# MSS_GPCFG_REG register map
Vendor: Texas Instruments
Peripheral module from a debugger description file (folder radar).
Registers are 32-bit, read-write, no defined reset value unless marked. A register's access mark holds for its fields unless they carry their own. Offsets are as the file gives them; lines under a group give offsets from that group; [hi:lo] are bit positions; {n}, {i} and the like mark numbered series; 'fields as' and 'values as' point back to an identical list; <NAME> marks a mode.

## MSS_GPCFG_REG
{0x0+4i} GPCFG{i} (i=0..4)
  [31:0] GPCFG{i} — General Purpose config register for SW use.
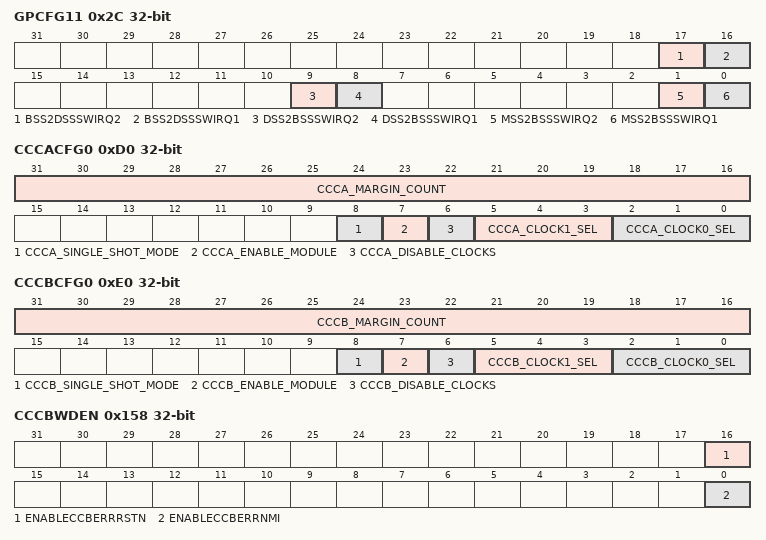
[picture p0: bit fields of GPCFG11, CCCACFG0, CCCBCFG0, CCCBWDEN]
0x2C GPCFG11 access not given
  [17] BSS2DSSSWIRQ2 — Self clearing register bit to generate interrupt to DSP from BSS. Writing a ‘1’ generates a pulse interrupt on one of the interrupt lines to DSP
  [16] BSS2DSSSWIRQ1 — Self clearing register bit to generate interrupt to DSP from BSS. Writing a ‘1’ generates a pulse interrupt on one of the interrupt lines to DSP
  [9] DSS2BSSSWIRQ2 — Self clearing register bit to generate interrupt to BSS from DSP. Writing a ‘1’ generates a pulse interrupt on one of the interrupt lines to BSS
  [8] DSS2BSSSWIRQ1 — Self clearing register bit to generate interrupt to BSS from DSP. Writing a ‘1’ generates a pulse interrupt on one of the interrupt lines to BSS
  [1] MSS2BSSSWIRQ2 — Self clearing register bit to generate interrupt to BSS from MSS. Writing a ‘1’ generates a pulse interrupt on one of the interrupt lines to BSS
  [0] MSS2BSSSWIRQ1 — Self clearing register bit to generate interrupt to BSS from MSS. Writing a ‘1’ generates a pulse interrupt on one of the interrupt lines to BSS
0xD0 CCCACFG0
  [31:16] CCCA_MARGIN_COUNT — Margin value for clock comparison in terms of counter1 clock.CCC error will not be generated if counter1 counter value is within “count1_expected_val” +/- MARGIN_COUNT
  [8] CCCA_SINGLE_SHOT_MODE — 1->Single shot mode, 0->Continuous mode
  [7] CCCA_ENABLE_MODULE — Enable for CCCA
  [6] CCCA_DISABLE_CLOCKS — 1->Clock gated to counter0 and counter1 0-> Normal mode
  [5:3] CCCA_CLOCK1_SEL — Selection for Clock 1 0->Select clock0_src[0] as source for counter1 1->Select clock0_src[1] as source for counter1 2->Select clock0_src[2] as source for counter1 ... 7->Select clock0_src[7] as source for counter1
  [2:0] CCCA_CLOCK0_SEL — Selection for Clock 0 0->Select clock0_src[0] as source for counter0 1->Select clock0_src[1] as source for counter0 2->Select clock0_src[2] as source for counter0 ... 7->Select clock0_src[7] as source for counter0
0xD4 CCCACFG1
  [31:0] CCCACFG1 — count0_expiry_val Counter 1 is compared for “count1_expected_val” +/- MARGIN_COUNT when counter0 expires after counting down from count0_expiry_val to 0
0xD8 CCCACFG2
  [31:0] CCCACFG2 — count1_expected_val Expected value of counter 1 when counter 0 expires after counting down from count0_expiry value
0xDC CCCACFG3
  [31:0] CCCACFG3 — Timeout Error Counter value in counter1 clock
0xE0 CCCBCFG0
  [31:16] CCCB_MARGIN_COUNT — Margin value for clock comparison in terms of counter1 clock.CCC error will not be generated if counter1 counter value is within “count1_expected_val” +/- MARGIN_COUNT
  [8] CCCB_SINGLE_SHOT_MODE — 1->Single shot mode, 0->Continuous mode
  [7] CCCB_ENABLE_MODULE — Enable for CCCB
  [6] CCCB_DISABLE_CLOCKS — 1->Clock gated to counter0 and counter1 0-> Normal mode
  [5:3] CCCB_CLOCK1_SEL — Selection for Clock 1 0->Select clock0_src[0] as source for counter1 1->Select clock0_src[1] as source for counter1 2->Select clock0_src[2] as source for counter1 ... 7->Select clock0_src[7] as source for counter1
  [2:0] CCCB_CLOCK0_SEL — Selection for Clock 0 0->Select clock0_src[0] as source for counter0 1->Select clock0_src[1] as source for counter0 2->Select clock0_src[2] as source for counter0 ... 7->Select clock0_src[7] as source for counter0
0xE4 CCCBCFG1
  [31:0] CCCBCFG1 — count0_expiry_val Counter 1 is compared for “count1_expected_val” +/- MARGIN_COUNT when counter0 expires after counting down from count0_expiry_val to 0
0xE8 CCCBCFG2
  [31:0] CCCBCFG2 — count1_expected_val Expected value of counter 1 when counter 0 expires after counting down from count0_expiry value
0xEC CCCBCFG3
  [31:0] CCCBCFG3 — Timeout Error Counter value in counter1 clock
0xF0 CCCACNTVAL ro
  [31:0] CCCACNTVAL — count1_val_out Real time value of counter1
0xF4 CCCBCNTVAL ro
  [31:0] CCCBCNTVAL — count1_val_out Real time value of counter1
0xF8 CCCABERRSTAT ro
  [31:0] CCCABERRSTAT — 7:0 : CCCA Error Status (for Debug) 15:8 : CCCB Error Status (for Debug) {3'd0, counter_error, counter_done, timeout_error, counter_error, Counter_done}
0xFC USERMODEEN
  [31:0] USERMODEEN — Write 0XADADADAD to enable user mode write access to MSS GPCFG space.
0x140 EPWMCFG
  [31:0] EPWMCFG — EPWM configuration [1:0] : 0->rampgen Frame start is SYNCIN to EPWM1 1->FRC Frame Start is SYNCIN to EPWM1 2,3-> External SYNCIN is SYNCIN to EPWM1 [3:2]: 0->rampgen Frame start is SYNCIN to EPWM2 1->FRC Frame Start is SYNCIN to EPWM2 2,3-> EPWM1 SYNCO is SYNCIN to EPWM2 [5:4]: 0->rampgen Frame start is SYNCIN to EPWM3 1->FRC Frame Start is SYNCIN to EPWM3 2,3-> EPWM2 SYNCO is SYNCIN to EPWM3 [8]:TBCLKEN for EPWM1 [9]:TBCLKEN for EPWM2 [10]:TBCLKEN for EPWM3
0x148 DMMSWINT0 access not given
  [31:0] DMMSWINT0 — HIL Intr0 muxed with frame start interrupt to DSP HIL Intr1 muxed with logical frame start interrupt to DSP HIL Intr2 muxed with Ping/Pong threshold trigger interrupt for DSP HIL Intr3 muxed with ADC data valid interrupt for DSP HIL Intr4 - HIL Intr8 : SW interrupt for DSP HIL Intr9 muxed with frame start interrupt to TPCC0 HIL Intr10 muxed with logical frame start interrupt to TPCC0 HIL Intr11 muxed with Ping/Pong threshold trigger interrupt for TPCC0 HIL Intr12 muxed with ADC data valid interrupt for TPCC0 HIL Intr13 - HIL Intr18 as SW interrupt for TPCC0 HIL Intr19 muxed with frame start interrupt to TPCC1 HIL Intr20 muxed with logical frame start interrupt to TPCC1 HIL Intr21 muxed with Ping/Pong threshold trigger interrupt for TPCC1 HIL Intr22 muxed with ADC data valid interrupt for TPCC1 HIL Intr23 - HIL Intr28 as SW interrupt for TPCC1 HIL Intr29 muxed with frame start interrupt to VIMMR4F HIL Intr30 muxed with logical frame start interrupt to VIMMR4F HIL Intr31 muxed with Ping/Pong threshold trigger interrupt for VIMMR4F HIL Intr32 muxed with ADC data valid interrupt for VIMMR4F HIL Intr33 - HIL Intr38 as SW interrupt for VIMMR4F HIL Intr39 muxed with frame start interrupt right at the source - propagates throughout the system as actual FRC output does. This is muxed with the frame start coming from BSS to TOP so that it propagates to MSS/DSS. HIL Intr40 muxed with frame start interrupt right at the source - propagates throughout the system as actual FRC output does. This is muxed with the ADC clock enable signal coming from FRC. Intr41 muxed with logical frame start interrupt right at the source (FRC) - propagates throughout the system Intr42 muxed with logical frame end interrupt right at the source (FRC) - propagates throughout the system Intr43 muxed with Ping/Pong threshold trigger interrupt right at the source - propagates throughout the system Intr44 muxed with ADC data valid interrupt right at the source - propagates throughout the system
0x14C DMMSWINT1 access not given
  [31:0] DMMSWINT1 — HIL Interrupts - MSB 32 bits [63:32]
0x150 DMMSWINTSEL0
  [31:0] DMMSWINTSEL0 — Mux control for HIL Interrupts - LSB 32 bits
0x154 DMMSWINTSEL1
  [31:0] DMMSWINTSEL1 — Mux control for HIL Interrupts - MSB 32 bits
0x158 CCCBWDEN
  [16] ENABLECCBERRRSTN — Enable CCCB error to generate WD restn.In this mode CCCB has to compare MSS CR4 clock to XTAL
  [0] ENABLECCBERRNMI — Enable CCCB error to generate NMI.In this mode CCCB has to compare MSS CR4 clock to XTAL
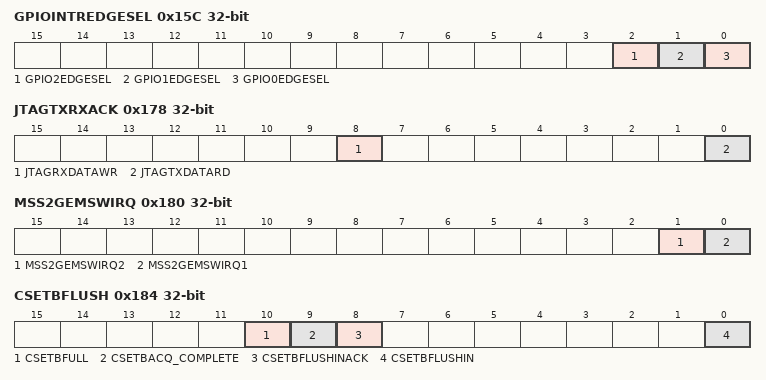
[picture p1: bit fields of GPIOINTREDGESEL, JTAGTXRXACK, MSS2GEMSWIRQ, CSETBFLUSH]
0x15C GPIOINTREDGESEL
  [2] GPIO2EDGESEL — 0:Posedge of GPIO2 generates interruptt to MSS CR4 and DSP 1:Negedge
  [1] GPIO1EDGESEL — 0:Posedge of GPIO1 generates interruptt to MSS CR4 and DSP 1:Negedge
  [0] GPIO0EDGESEL — 0:Posedge of GPIO0 generates interruptt to MSS CR4 and DSP 1:Negedge
0x164 PWMDMATRIGEN
  [3:0] PWMDMATRIGEN — PWMDMATRIGEN[0]: "1" -> Mux epwm1a instead of mss_event_gen_1_frc to DMA PWMDMATRIGEN[1]: "1" -> Mux epwm1b instead of mss_event_gen_1_frc to DMA PWMDMATRIGEN[2]: "1" -> Mux epwm2a instead of mss_event_gen_1_frc to DMA PWMDMATRIGEN[3]: "1" -> Mux epwm2b instead of mss_event_gen_1_frc to DMA
0x168 JTAGTXDATA ro
  [31:0] JTAGTXDATA — Transmit Data. This register is used to pass data to the system security logic
0x16C JTAGTXCONTROL ro
  [31:0] JTAGTXCONTROL — Provides the handshake for the JTAGTXDATA Register and can also be used to pass control information to the system security logic. Only bits [31:1] are valid
0x170 JTAGRXDATA
  [31:0] JTAGRXDATA — Receive data. This register is used to pass data from the system security logic
0x178 JTAGTXRXACK
  [8] JTAGRXDATAWR — Indication from system security logic that JTAGRXDATA is valid
  [0] JTAGTXDATARD — Indication from the system security logic that JTAGTXDATA has been accepted
0x17C JTAGRXCONTROL
  [31:0] JTAGRXCONTROL — Provides the handshake for the JTAGRXDATA Register and can also be used to pass control information from the system security logic. Only bits [31:1] is used.
0x180 MSS2GEMSWIRQ access not given
  [1] MSS2GEMSWIRQ2 — Self clearing register bit to generate interrupt to DSP from MSS. Writing a ‘1’ generates a pulse interrupt on one of the interrupt lines to DSP
  [0] MSS2GEMSWIRQ1 — Self clearing register bit to generate interrupt to DSP from MSS. Writing a ‘1’ generates a pulse interrupt on one of the interrupt lines to DSP
0x184 CSETBFLUSH access per field
  [10] CSETBFULL ro — When HIGH indicates that the ETB RAM has overflowed or wrapped around to address zero
  [9] CSETBACQ_COMPLETE ro — When HIGH, indicates that trace acquisition is complete by ETB, that is, the trigger counter is at zero
  [8] CSETBFLUSHINACK ro — Return acknowledgement to CSETBFLUSHIN
  [0] CSETBFLUSHIN rw — External control used to assert the ATB signal AFVALIDS and drain any historical FIFO information on the bus
